VERSION ""

NS_ :

BS_:

BU_:

BO_ 2381740030 GS_Resets: 8 Vector__XXX
 SG_ GS_LatchReset : 0|1@1+ (1,0) [0|1] "" Vector__XXX

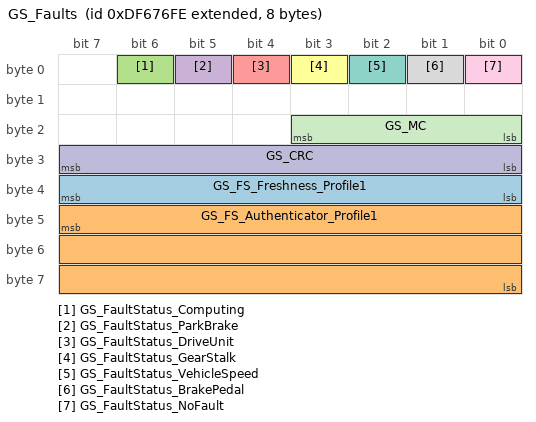
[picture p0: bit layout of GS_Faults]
BO_ 2381739774 GS_Faults: 8 Vector__XXX
 SG_ GS_FS_Freshness_Profile1 : 39|8@0+ (1,0) [0|255] "" Vector__XXX
 SG_ GS_FS_Authenticator_Profile1 : 47|24@0+ (1,0) [0|16777215] "" Vector__XXX
 SG_ GS_FaultStatus_Computing : 6|1@1+ (1,0) [0|1] "" Vector__XXX
 SG_ GS_FaultStatus_ParkBrake : 5|1@1+ (1,0) [0|1] "" Vector__XXX
 SG_ GS_FaultStatus_DriveUnit : 4|1@1+ (1,0) [0|1] "" Vector__XXX
 SG_ GS_FaultStatus_GearStalk : 3|1@1+ (1,0) [0|1] "" Vector__XXX
 SG_ GS_FaultStatus_VehicleSpeed : 2|1@1+ (1,0) [0|1] "" Vector__XXX
 SG_ GS_FaultStatus_BrakePedal : 1|1@1+ (1,0) [0|1] "" Vector__XXX
 SG_ GS_FaultStatus_NoFault : 0|1@1+ (1,0) [0|1] "" Vector__XXX
 SG_ GS_CRC : 24|8@1+ (1,0) [0|255] "" Vector__XXX
 SG_ GS_MC : 16|4@1+ (1,0) [0|15] "" Vector__XXX

CM_ BO_ 2381740030 "For DEBUG-TEST only! Consist of signals that can replace AI GS Request, HMI 3 GS Request and state of gearbox interlock signals.";
CM_ BO_ 2381739774 "For DEBUG-TEST only! Consist of signals that can replace AI GS Request, HMI 3 GS Request and state of gearbox interlock signals.";
BA_DEF_ BO_  "Producer" STRING ;
BA_DEF_ SG_  "SigType" ENUM  "Default","Range","RangeSigned","ASCII","Discrete","Control","ReferencePGN","DTC","StringDelimiter","StringLength","StringLengthControl","MessageCounter","MessageChecksum";
BA_DEF_ SG_  "GenSigEVName" STRING ;
BA_DEF_ SG_  "GenSigILSupport" ENUM  "No","Yes";
BA_DEF_ SG_  "GenSigSendType" ENUM  "Cyclic","OnWrite","OnWriteWithRepetition","OnChange","OnChangeWithRepetition","IfActive","IfActiveWithRepetition","NoSigSendType";
BA_DEF_ BO_  "GenMsgILSupport" ENUM  "No","Yes";
BA_DEF_ BU_  "NmStationAddress" INT 0 255;
BA_DEF_ BO_  "GenMsgSendType" ENUM  "cyclic","NotUsed","IfActive","NotUsed","NotUsed","NotUsed","NotUsed","NotUsed","noMsgSendType";
BA_DEF_ BO_  "GenMsgRequestable" INT 0 1;
BA_DEF_ BO_  "GenMsgCycleTime" INT 0 3600000;
BA_DEF_  "DBName" STRING ;
BA_DEF_  "BusType" STRING ;
BA_DEF_  "ProtocolType" STRING ;
BA_DEF_ BO_  "VFrameFormat" ENUM  "StandardCAN","ExtendedCAN","reserved","J1939PG";
BA_DEF_DEF_ "Producer" "DTS" ;
BA_DEF_DEF_  "SigType" "Default";
BA_DEF_DEF_  "GenSigEVName" "Env@Nodename_@Signame";
BA_DEF_DEF_  "GenSigILSupport" "Yes";
BA_DEF_DEF_  "GenSigSendType" "NoSigSendType";
BA_DEF_DEF_  "GenMsgILSupport" "Yes";
BA_DEF_DEF_  "NmStationAddress" 254;
BA_DEF_DEF_  "GenMsgSendType" "noMsgSendType";
BA_DEF_DEF_  "GenMsgRequestable" 1;
BA_DEF_DEF_  "GenMsgCycleTime" 0;
BA_DEF_DEF_  "DBName" "";
BA_DEF_DEF_  "BusType" "CAN";
BA_DEF_DEF_  "ProtocolType" "J1939";
BA_DEF_DEF_  "VFrameFormat" "J1939PG";
BA_ "DBName" "GearSelector";
BA_ "GenMsgSendType" BO_ 2381740030 0;
BA_ "GenMsgCycleTime" BO_ 2381740030 100;
BA_ "GenMsgSendType" BO_ 2381739774 0;
BA_ "GenMsgCycleTime" BO_ 2381739774 100;
BA_ "SigType" SG_ 2381739774 GS_CRC 12;
BA_ "SigType" SG_ 2381739774 GS_MC 11;
